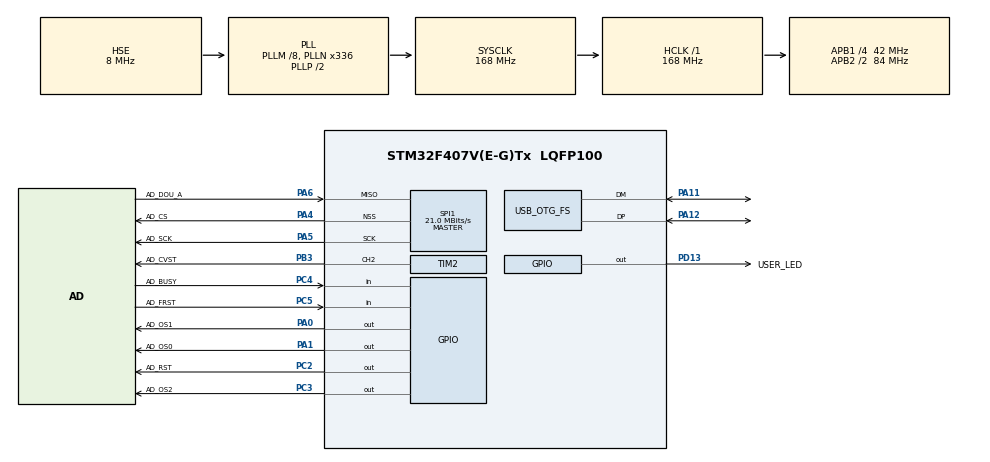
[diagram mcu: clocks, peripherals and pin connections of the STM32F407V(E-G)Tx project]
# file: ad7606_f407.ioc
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Dma.Request0=SPI1_RX
Dma.SPI1_RX.0.Direction=DMA_PERIPH_TO_MEMORY
Dma.SPI1_RX.0.FIFOMode=DMA_FIFOMODE_DISABLE
Dma.SPI1_RX.0.Instance=DMA2_Stream0
Dma.SPI1_RX.0.MemDataAlignment=DMA_MDATAALIGN_HALFWORD
Dma.SPI1_RX.0.MemInc=DMA_MINC_ENABLE
Dma.SPI1_RX.0.Mode=DMA_NORMAL
Dma.SPI1_RX.0.PeriphDataAlignment=DMA_PDATAALIGN_HALFWORD
Dma.SPI1_RX.0.PeriphInc=DMA_PINC_DISABLE
Dma.SPI1_RX.0.Priority=DMA_PRIORITY_LOW
Mcu.Family=STM32F4
Mcu.Name=STM32F407V(E-G)Tx
Mcu.Package=LQFP100
NVIC.DMA2_Stream0_IRQn=true\:0\:0\:false\:false\:true\:false\:true\:true
NVIC.OTG_FS_IRQn=true\:0\:0\:false\:false\:true\:false\:true\:true
NVIC.PriorityGroup=NVIC_PRIORITYGROUP_4
PA0-WKUP.GPIO_Label=AD_OS1
PA0-WKUP.Signal=GPIO_Output
PA1.GPIO_Label=AD_OS0
PA1.Signal=GPIO_Output
PA11.Mode=Device_Only
PA11.Signal=USB_OTG_FS_DM
PA12.Mode=Device_Only
PA12.Signal=USB_OTG_FS_DP
PA4.GPIO_Label=AD_CS
PA4.GPIO_PuPd=GPIO_PULLUP
PA4.Mode=NSS_Signal_Hard_Output
PA4.Signal=SPI1_NSS
PA5.GPIO_Label=AD_SCK
PA5.Mode=RX_Only_Simplex_Unidirect_Master
PA5.Signal=SPI1_SCK
PA6.GPIO_Label=AD_DOU_A
PA6.Mode=RX_Only_Simplex_Unidirect_Master
PA6.Signal=SPI1_MISO
PB3.GPIO_Label=AD_CVST
PB3.Signal=S_TIM2_CH2
PC2.GPIO_Label=AD_RST
PC2.Signal=GPIO_Output
PC3.GPIO_Label=AD_OS2
PC3.Signal=GPIO_Output
PC4.GPIO_Label=AD_BUSY
PC4.Signal=GPIO_Input
PC5.GPIO_Label=AD_FRST
PC5.Signal=GPIO_Input
PD13.GPIO_Label=USER_LED
PD13.Signal=GPIO_Output
PH0-OSC_IN.Mode=HSE-External-Oscillator
PH0-OSC_IN.Signal=RCC_OSC_IN
PH1-OSC_OUT.Mode=HSE-External-Oscillator
PH1-OSC_OUT.Signal=RCC_OSC_OUT
ProjectManager.HeapSize=0x2000
ProjectManager.StackSize=0x4000
ProjectManager.TargetToolchain=STM32CubeIDE
RCC.48MHZClocksFreq_Value=48000000
RCC.AHBFreq_Value=168000000
RCC.APB1CLKDivider=RCC_HCLK_DIV4
RCC.APB1Freq_Value=42000000
RCC.APB1TimFreq_Value=84000000
RCC.APB2CLKDivider=RCC_HCLK_DIV2
RCC.APB2Freq_Value=84000000
RCC.APB2TimFreq_Value=168000000
RCC.CortexFreq_Value=168000000
RCC.HCLKFreq_Value=168000000
RCC.HSE_VALUE=8000000
RCC.HSI_VALUE=16000000
RCC.LSE_VALUE=32768
RCC.PLLM=8
RCC.PLLN=336
RCC.PLLQ=7
RCC.SYSCLKFreq_VALUE=168000000
RCC.SYSCLKSource=RCC_SYSCLKSOURCE_PLLCLK
RCC.VCOOutputFreq_Value=336000000
SH.S_TIM2_CH2.0=TIM2_CH2,PWM Generation2 CH2
SPI1.BaudRatePrescaler=SPI_BAUDRATEPRESCALER_4
SPI1.CLKPhase=SPI_PHASE_2EDGE
SPI1.CLKPolarity=SPI_POLARITY_HIGH
SPI1.CalculateBaudRate=21.0 MBits/s
SPI1.DataSize=SPI_DATASIZE_16BIT
SPI1.Direction=SPI_DIRECTION_2LINES_RXONLY
SPI1.Mode=SPI_MODE_MASTER
SPI1.VirtualNSS=VM_NSSHARD
SPI1.VirtualType=VM_MASTER
TIM2.Channel-PWM\ Generation2\ CH2=TIM_CHANNEL_2
TIM2.Period=99
TIM2.Prescaler=84
TIM2.Pulse-PWM\ Generation2\ CH2=95
USB_DEVICE.CLASS_NAME_FS=CDC
USB_DEVICE.VirtualMode-CDC_FS=Cdc
USB_DEVICE.VirtualModeFS=Cdc_FS
USB_OTG_FS.VirtualMode=Device_Only
VP_TIM2_VS_ClockSourceINT.Mode=Internal
VP_USB_DEVICE_VS_USB_DEVICE_CDC_FS.Mode=CDC_FS
board=custom

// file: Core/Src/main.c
/* USER CODE BEGIN Header */
/**
  ******************************************************************************
  * @file           : main.c
  * @brief          : Main program body
  ******************************************************************************
  * @attention
  *
  * Copyright (c) 2022 STMicroelectronics.
  * All rights reserved.
  *
  * This software is licensed under terms that can be found in the LICENSE file
  * in the root directory of this software component.
  * If no LICENSE file comes with this software, it is provided AS-IS.
  *
  ******************************************************************************
  */
/* USER CODE END Header */
#include "main.h"
#include "usb_device.h"

/* USER CODE BEGIN Includes */
#include "usbd_cdc_if.h"

/* USER CODE END Includes */

SPI_HandleTypeDef hspi1;
DMA_HandleTypeDef hdma_spi1_rx;

TIM_HandleTypeDef htim2;

/* USER CODE BEGIN PV */
int16_t adcDataBuf[ADC_DATA_BUF_SIZE] = {0};

float voltageDataBuf[VOLTAGE_DATA_BUF_SIZE];

char usbTxDataBuf[USB_TX_DATA_BUF_SIZE] = {0};

AD7606_HandleTyeDef had7606;

/* USER CODE END PV */

void SystemClock_Config(void);
static void MX_GPIO_Init(void);
static void MX_DMA_Init(void);
static void MX_SPI1_Init(void);
static void MX_TIM2_Init(void);

int main(void)
{

  /* MCU Configuration--------------------------------------------------------*/

  /* Reset of all peripherals, Initializes the Flash interface and the Systick. */
  HAL_Init();

  /* USER CODE BEGIN Init */
  AD7606_Init(&had7606, &hspi1, &hdma_spi1_rx, &htim2);

  /* USER CODE END Init */

  /* Configure the system clock */
  SystemClock_Config();

  /* Initialize all configured peripherals */
  MX_GPIO_Init();
  MX_DMA_Init();
  MX_SPI1_Init();
  MX_TIM2_Init();
  MX_USB_DEVICE_Init();
  /* USER CODE BEGIN 2 */

  AD7606_OS_SET(1);
  AD7606_RST();
  AD7606_CVST_START(&had7606);

  /* USER CODE END 2 */

  /* Infinite loop */
  while (1)
  {

    /* USER CODE BEGIN 3 */

//	  AD7606_StartReadBytes(&had7606, adcDataBuf, ADC_DATA_BUF_SIZE, 10);
	  AD7606_StartReadBytes_DMA(&had7606, adcDataBuf, ADC_DATA_BUF_SIZE);
	  AD7606_ConvertToVoltage(READ_8_CHANNEL, adcDataBuf, voltageDataBuf);

//	  CDC_Transmit_FS((uint8_t*)(itoa((int)adcDataBuf[ADC_CHANNEL_7], usbTxDataBuf, 10)), USB_TX_DATA_BUF_SIZE);

  }
  /* USER CODE END 3 */
}

void SystemClock_Config(void)
{
  RCC_OscInitTypeDef RCC_OscInitStruct = {0};
  RCC_ClkInitTypeDef RCC_ClkInitStruct = {0};

  /** Configure the main internal regulator output voltage
  */
  __HAL_RCC_PWR_CLK_ENABLE();
  __HAL_PWR_VOLTAGESCALING_CONFIG(PWR_REGULATOR_VOLTAGE_SCALE1);

  /** Initializes the RCC Oscillators according to the specified parameters
  * in the RCC_OscInitTypeDef structure.
  */
  RCC_OscInitStruct.OscillatorType = RCC_OSCILLATORTYPE_HSE;
  RCC_OscInitStruct.HSEState = RCC_HSE_ON;
  RCC_OscInitStruct.PLL.PLLState = RCC_PLL_ON;
  RCC_OscInitStruct.PLL.PLLSource = RCC_PLLSOURCE_HSE;
  RCC_OscInitStruct.PLL.PLLM = 8;
  RCC_OscInitStruct.PLL.PLLN = 336;
  RCC_OscInitStruct.PLL.PLLP = RCC_PLLP_DIV2;
  RCC_OscInitStruct.PLL.PLLQ = 7;
  if (HAL_RCC_OscConfig(&RCC_OscInitStruct) != HAL_OK)
  {
    Error_Handler();
  }

  /** Initializes the CPU, AHB and APB buses clocks
  */
  RCC_ClkInitStruct.ClockType = RCC_CLOCKTYPE_HCLK|RCC_CLOCKTYPE_SYSCLK
                              |RCC_CLOCKTYPE_PCLK1|RCC_CLOCKTYPE_PCLK2;
  RCC_ClkInitStruct.SYSCLKSource = RCC_SYSCLKSOURCE_PLLCLK;
  RCC_ClkInitStruct.AHBCLKDivider = RCC_SYSCLK_DIV1;
  RCC_ClkInitStruct.APB1CLKDivider = RCC_HCLK_DIV4;
  RCC_ClkInitStruct.APB2CLKDivider = RCC_HCLK_DIV2;

  if (HAL_RCC_ClockConfig(&RCC_ClkInitStruct, FLASH_LATENCY_5) != HAL_OK)
  {
    Error_Handler();
  }
}

static void MX_SPI1_Init(void)
{

  /* SPI1 parameter configuration*/
  hspi1.Instance = SPI1;
  hspi1.Init.Mode = SPI_MODE_MASTER;
  hspi1.Init.Direction = SPI_DIRECTION_2LINES_RXONLY;
  hspi1.Init.DataSize = SPI_DATASIZE_16BIT;
  hspi1.Init.CLKPolarity = SPI_POLARITY_HIGH;
  hspi1.Init.CLKPhase = SPI_PHASE_2EDGE;
  hspi1.Init.NSS = SPI_NSS_HARD_OUTPUT;
  hspi1.Init.BaudRatePrescaler = SPI_BAUDRATEPRESCALER_4;
  hspi1.Init.FirstBit = SPI_FIRSTBIT_MSB;
  hspi1.Init.TIMode = SPI_TIMODE_DISABLE;
  hspi1.Init.CRCCalculation = SPI_CRCCALCULATION_DISABLE;
  hspi1.Init.CRCPolynomial = 10;
  if (HAL_SPI_Init(&hspi1) != HAL_OK)
  {
    Error_Handler();
  }

}

static void MX_TIM2_Init(void)
{

  TIM_ClockConfigTypeDef sClockSourceConfig = {0};
  TIM_MasterConfigTypeDef sMasterConfig = {0};
  TIM_OC_InitTypeDef sConfigOC = {0};

  htim2.Instance = TIM2;
  htim2.Init.Prescaler = 84;
  htim2.Init.CounterMode = TIM_COUNTERMODE_UP;
  htim2.Init.Period = 99;
  htim2.Init.ClockDivision = TIM_CLOCKDIVISION_DIV1;
  htim2.Init.AutoReloadPreload = TIM_AUTORELOAD_PRELOAD_DISABLE;
  if (HAL_TIM_Base_Init(&htim2) != HAL_OK)
  {
    Error_Handler();
  }
  sClockSourceConfig.ClockSource = TIM_CLOCKSOURCE_INTERNAL;
  if (HAL_TIM_ConfigClockSource(&htim2, &sClockSourceConfig) != HAL_OK)
  {
    Error_Handler();
  }
  if (HAL_TIM_PWM_Init(&htim2) != HAL_OK)
  {
    Error_Handler();
  }
  sMasterConfig.MasterOutputTrigger = TIM_TRGO_RESET;
  sMasterConfig.MasterSlaveMode = TIM_MASTERSLAVEMODE_DISABLE;
  if (HAL_TIMEx_MasterConfigSynchronization(&htim2, &sMasterConfig) != HAL_OK)
  {
    Error_Handler();
  }
  sConfigOC.OCMode = TIM_OCMODE_PWM1;
  sConfigOC.Pulse = 95;
  sConfigOC.OCPolarity = TIM_OCPOLARITY_HIGH;
  sConfigOC.OCFastMode = TIM_OCFAST_DISABLE;
  if (HAL_TIM_PWM_ConfigChannel(&htim2, &sConfigOC, TIM_CHANNEL_2) != HAL_OK)
  {
    Error_Handler();
  }
  HAL_TIM_MspPostInit(&htim2);

}

static void MX_DMA_Init(void)
{

  /* DMA controller clock enable */
  __HAL_RCC_DMA2_CLK_ENABLE();

  /* DMA interrupt init */
  /* DMA2_Stream0_IRQn interrupt configuration */
  HAL_NVIC_SetPriority(DMA2_Stream0_IRQn, 0, 0);
  HAL_NVIC_EnableIRQ(DMA2_Stream0_IRQn);

}

static void MX_GPIO_Init(void)
{
  GPIO_InitTypeDef GPIO_InitStruct = {0};

  /* GPIO Ports Clock Enable */
  __HAL_RCC_GPIOH_CLK_ENABLE();
  __HAL_RCC_GPIOC_CLK_ENABLE();
  __HAL_RCC_GPIOA_CLK_ENABLE();
  __HAL_RCC_GPIOD_CLK_ENABLE();
  __HAL_RCC_GPIOB_CLK_ENABLE();

  /*Configure GPIO pin Output Level */
  HAL_GPIO_WritePin(GPIOC, AD_RST_Pin|AD_OS2_Pin, GPIO_PIN_RESET);

  /*Configure GPIO pin Output Level */
  HAL_GPIO_WritePin(GPIOA, AD_OS1_Pin|AD_OS0_Pin, GPIO_PIN_RESET);

  /*Configure GPIO pin Output Level */
  HAL_GPIO_WritePin(USER_LED_GPIO_Port, USER_LED_Pin, GPIO_PIN_RESET);

  /*Configure GPIO pins : AD_RST_Pin AD_OS2_Pin */
  GPIO_InitStruct.Pin = AD_RST_Pin|AD_OS2_Pin;
  GPIO_InitStruct.Mode = GPIO_MODE_OUTPUT_PP;
  GPIO_InitStruct.Pull = GPIO_NOPULL;
  GPIO_InitStruct.Speed = GPIO_SPEED_FREQ_LOW;
  HAL_GPIO_Init(GPIOC, &GPIO_InitStruct);

  /*Configure GPIO pins : AD_OS1_Pin AD_OS0_Pin */
  GPIO_InitStruct.Pin = AD_OS1_Pin|AD_OS0_Pin;
  GPIO_InitStruct.Mode = GPIO_MODE_OUTPUT_PP;
  GPIO_InitStruct.Pull = GPIO_NOPULL;
  GPIO_InitStruct.Speed = GPIO_SPEED_FREQ_LOW;
  HAL_GPIO_Init(GPIOA, &GPIO_InitStruct);

  /*Configure GPIO pins : AD_BUSY_Pin AD_FRST_Pin */
  GPIO_InitStruct.Pin = AD_BUSY_Pin|AD_FRST_Pin;
  GPIO_InitStruct.Mode = GPIO_MODE_INPUT;
  GPIO_InitStruct.Pull = GPIO_NOPULL;
  HAL_GPIO_Init(GPIOC, &GPIO_InitStruct);

  /*Configure GPIO pin : USER_LED_Pin */
  GPIO_InitStruct.Pin = USER_LED_Pin;
  GPIO_InitStruct.Mode = GPIO_MODE_OUTPUT_PP;
  GPIO_InitStruct.Pull = GPIO_NOPULL;
  GPIO_InitStruct.Speed = GPIO_SPEED_FREQ_LOW;
  HAL_GPIO_Init(USER_LED_GPIO_Port, &GPIO_InitStruct);

}

void Error_Handler(void)
{
  __disable_irq();
  while (1)
  {
  }
}
